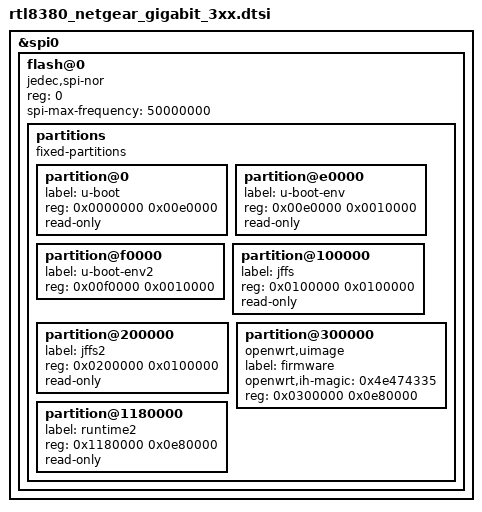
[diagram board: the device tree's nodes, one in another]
// SPDX-License-Identifier: GPL-2.0-or-later

#include "rtl8380_netgear_gigabit.dtsi"

&spi0 {
	status = "okay";

	flash@0 {
		compatible = "jedec,spi-nor";
		reg = <0>;
		spi-max-frequency = <50000000>;

		partitions {
			compatible = "fixed-partitions";
			#address-cells = <1>;
			#size-cells = <1>;

			partition@0 {
				label = "u-boot";
				reg = <0x0000000 0x00e0000>;
				read-only;
			};

			partition@e0000 {
				label = "u-boot-env";
				reg = <0x00e0000 0x0010000>;
				read-only;
			};

			partition@f0000 {
				label = "u-boot-env2";
				reg = <0x00f0000 0x0010000>;
			};

			partition@100000 {
				label = "jffs";
				reg = <0x0100000 0x0100000>;
				read-only;
			};

			partition@200000 {
				label = "jffs2";
				reg = <0x0200000 0x0100000>;
				read-only;
			};

			partition@300000 {
				label = "firmware";
				compatible = "openwrt,uimage", "denx,uimage";
				openwrt,ih-magic = <0x4e474335>;
				reg = <0x0300000 0x0e80000>;
			};

			partition@1180000 {
				label = "runtime2";
				reg = <0x1180000 0x0e80000>;
				read-only;
			};
		};
	};
};
